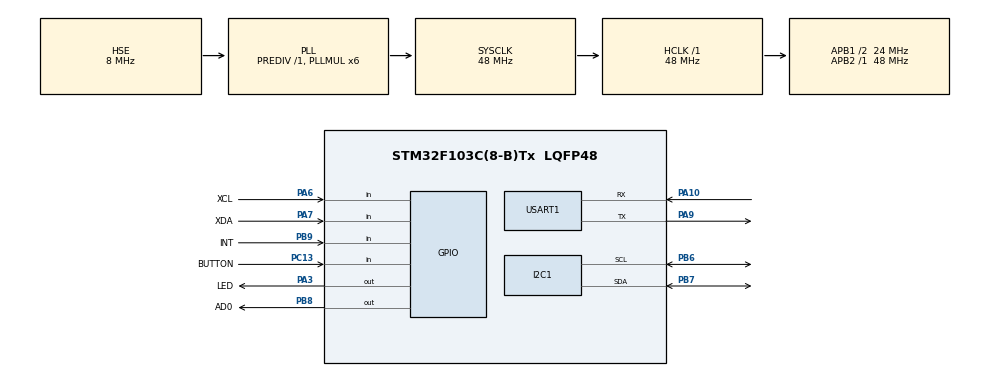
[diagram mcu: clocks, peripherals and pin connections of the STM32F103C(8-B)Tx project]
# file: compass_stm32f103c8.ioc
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Mcu.Family=STM32F1
Mcu.Name=STM32F103C(8-B)Tx
Mcu.Package=LQFP48
NVIC.PriorityGroup=NVIC_PRIORITYGROUP_4
NVIC.TIM2_IRQn=true\:0\:0\:false\:false\:true\:true\:true\:true
NVIC.USART1_IRQn=true\:0\:0\:false\:false\:true\:true\:true\:true
PA10.Mode=Asynchronous
PA10.Signal=USART1_RX
PA13.Mode=Serial_Wire
PA13.Signal=SYS_JTMS-SWDIO
PA14.Mode=Serial_Wire
PA14.Signal=SYS_JTCK-SWCLK
PA3.GPIO_Label=LED
PA3.Signal=GPIO_Output
PA6.GPIO_Label=XCL
PA6.Signal=GPIO_Input
PA7.GPIO_Label=XDA
PA7.Signal=GPIO_Input
PA9.Mode=Asynchronous
PA9.Signal=USART1_TX
PB6.Mode=I2C
PB6.Signal=I2C1_SCL
PB7.Mode=I2C
PB7.Signal=I2C1_SDA
PB8.GPIO_Label=AD0
PB8.GPIO_ModeDefaultOutputPP=GPIO_MODE_OUTPUT_OD
PB8.GPIO_PuPd=GPIO_NOPULL
PB8.PinState=GPIO_PIN_RESET
PB8.Signal=GPIO_Output
PB9.GPIO_Label=INT
PB9.Signal=GPIO_Input
PC13-TAMPER-RTC.GPIO_Label=BUTTON
PC13-TAMPER-RTC.GPIO_PuPd=GPIO_PULLUP
PC13-TAMPER-RTC.Signal=GPIO_Input
PD0-OSC_IN.Mode=HSE-External-Oscillator
PD0-OSC_IN.Signal=RCC_OSC_IN
PD1-OSC_OUT.Mode=HSE-External-Oscillator
PD1-OSC_OUT.Signal=RCC_OSC_OUT
ProjectManager.HeapSize=0x200
ProjectManager.StackSize=0x400
ProjectManager.TargetToolchain=STM32CubeIDE
RCC.AHBFreq_Value=48000000
RCC.APB1CLKDivider=RCC_HCLK_DIV2
RCC.APB1Freq_Value=24000000
RCC.APB1TimFreq_Value=48000000
RCC.APB2Freq_Value=48000000
RCC.APB2TimFreq_Value=48000000
RCC.HCLKFreq_Value=48000000
RCC.PLLMUL=RCC_PLL_MUL6
RCC.PLLSourceVirtual=RCC_PLLSOURCE_HSE
RCC.SYSCLKFreq_VALUE=48000000
RCC.SYSCLKSource=RCC_SYSCLKSOURCE_PLLCLK
RCC.USBFreq_Value=48000000
TIM2.Period=2000-1
TIM2.Prescaler=480-1
USART1.VirtualMode=VM_ASYNC
VP_TIM2_VS_ClockSourceINT.Mode=Internal
board=custom

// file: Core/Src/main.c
/* USER CODE BEGIN Header */
/**
  ******************************************************************************
  * @file           : main.c
  * @brief          : Main program body
  ******************************************************************************
  * @attention
  *
  * Copyright (c) 2023 STMicroelectronics.
  * All rights reserved.
  *
  * This software is licensed under terms that can be found in the LICENSE file
  * in the root directory of this software component.
  * If no LICENSE file comes with this software, it is provided AS-IS.
  *
  ******************************************************************************
  */
/* USER CODE END Header */
#include "main.h"

/* USER CODE BEGIN Includes */
#include "../user/main-app.h"
/* USER CODE END Includes */

I2C_HandleTypeDef hi2c1;

TIM_HandleTypeDef htim2;

UART_HandleTypeDef huart1;

void SystemClock_Config(void);
static void MX_GPIO_Init(void);
static void MX_I2C1_Init(void);
static void MX_USART1_UART_Init(void);
static void MX_TIM2_Init(void);

int main(void)
{

  /* MCU Configuration--------------------------------------------------------*/

  /* Reset of all peripherals, Initializes the Flash interface and the Systick. */
  HAL_Init();

  /* Configure the system clock */
  SystemClock_Config();

  /* USER CODE BEGIN SysInit */
  HAL_Delay(100);
  /* USER CODE END SysInit */

  /* Initialize all configured peripherals */
  MX_GPIO_Init();
  MX_I2C1_Init();
  MX_USART1_UART_Init();
  MX_TIM2_Init();
  /* USER CODE BEGIN 2 */
  mainInit();
  /* USER CODE END 2 */

  /* Infinite loop */
  while (1)
  {

    /* USER CODE BEGIN 3 */
	  mainProcess();
  }
  /* USER CODE END 3 */
}

void SystemClock_Config(void)
{
  RCC_OscInitTypeDef RCC_OscInitStruct = {0};
  RCC_ClkInitTypeDef RCC_ClkInitStruct = {0};

  /** Initializes the RCC Oscillators according to the specified parameters
  * in the RCC_OscInitTypeDef structure.
  */
  RCC_OscInitStruct.OscillatorType = RCC_OSCILLATORTYPE_HSE;
  RCC_OscInitStruct.HSEState = RCC_HSE_ON;
  RCC_OscInitStruct.HSEPredivValue = RCC_HSE_PREDIV_DIV1;
  RCC_OscInitStruct.HSIState = RCC_HSI_ON;
  RCC_OscInitStruct.PLL.PLLState = RCC_PLL_ON;
  RCC_OscInitStruct.PLL.PLLSource = RCC_PLLSOURCE_HSE;
  RCC_OscInitStruct.PLL.PLLMUL = RCC_PLL_MUL6;
  if (HAL_RCC_OscConfig(&RCC_OscInitStruct) != HAL_OK)
  {
    Error_Handler();
  }

  /** Initializes the CPU, AHB and APB buses clocks
  */
  RCC_ClkInitStruct.ClockType = RCC_CLOCKTYPE_HCLK|RCC_CLOCKTYPE_SYSCLK
                              |RCC_CLOCKTYPE_PCLK1|RCC_CLOCKTYPE_PCLK2;
  RCC_ClkInitStruct.SYSCLKSource = RCC_SYSCLKSOURCE_PLLCLK;
  RCC_ClkInitStruct.AHBCLKDivider = RCC_SYSCLK_DIV1;
  RCC_ClkInitStruct.APB1CLKDivider = RCC_HCLK_DIV2;
  RCC_ClkInitStruct.APB2CLKDivider = RCC_HCLK_DIV1;

  if (HAL_RCC_ClockConfig(&RCC_ClkInitStruct, FLASH_LATENCY_1) != HAL_OK)
  {
    Error_Handler();
  }
}

static void MX_I2C1_Init(void)
{

  hi2c1.Instance = I2C1;
  hi2c1.Init.ClockSpeed = 100000;
  hi2c1.Init.DutyCycle = I2C_DUTYCYCLE_2;
  hi2c1.Init.OwnAddress1 = 0;
  hi2c1.Init.AddressingMode = I2C_ADDRESSINGMODE_7BIT;
  hi2c1.Init.DualAddressMode = I2C_DUALADDRESS_DISABLE;
  hi2c1.Init.OwnAddress2 = 0;
  hi2c1.Init.GeneralCallMode = I2C_GENERALCALL_DISABLE;
  hi2c1.Init.NoStretchMode = I2C_NOSTRETCH_DISABLE;
  if (HAL_I2C_Init(&hi2c1) != HAL_OK)
  {
    Error_Handler();
  }

}

static void MX_TIM2_Init(void)
{

  TIM_ClockConfigTypeDef sClockSourceConfig = {0};
  TIM_MasterConfigTypeDef sMasterConfig = {0};

  htim2.Instance = TIM2;
  htim2.Init.Prescaler = 480-1;
  htim2.Init.CounterMode = TIM_COUNTERMODE_UP;
  htim2.Init.Period = 2000-1;
  htim2.Init.ClockDivision = TIM_CLOCKDIVISION_DIV1;
  htim2.Init.AutoReloadPreload = TIM_AUTORELOAD_PRELOAD_DISABLE;
  if (HAL_TIM_Base_Init(&htim2) != HAL_OK)
  {
    Error_Handler();
  }
  sClockSourceConfig.ClockSource = TIM_CLOCKSOURCE_INTERNAL;
  if (HAL_TIM_ConfigClockSource(&htim2, &sClockSourceConfig) != HAL_OK)
  {
    Error_Handler();
  }
  sMasterConfig.MasterOutputTrigger = TIM_TRGO_RESET;
  sMasterConfig.MasterSlaveMode = TIM_MASTERSLAVEMODE_DISABLE;
  if (HAL_TIMEx_MasterConfigSynchronization(&htim2, &sMasterConfig) != HAL_OK)
  {
    Error_Handler();
  }

}

static void MX_USART1_UART_Init(void)
{

  huart1.Instance = USART1;
  huart1.Init.BaudRate = 115200;
  huart1.Init.WordLength = UART_WORDLENGTH_8B;
  huart1.Init.StopBits = UART_STOPBITS_1;
  huart1.Init.Parity = UART_PARITY_NONE;
  huart1.Init.Mode = UART_MODE_TX_RX;
  huart1.Init.HwFlowCtl = UART_HWCONTROL_NONE;
  huart1.Init.OverSampling = UART_OVERSAMPLING_16;
  if (HAL_UART_Init(&huart1) != HAL_OK)
  {
    Error_Handler();
  }

}

static void MX_GPIO_Init(void)
{
  GPIO_InitTypeDef GPIO_InitStruct = {0};

  /* GPIO Ports Clock Enable */
  __HAL_RCC_GPIOC_CLK_ENABLE();
  __HAL_RCC_GPIOD_CLK_ENABLE();
  __HAL_RCC_GPIOA_CLK_ENABLE();
  __HAL_RCC_GPIOB_CLK_ENABLE();

  /*Configure GPIO pin Output Level */
  HAL_GPIO_WritePin(LED_GPIO_Port, LED_Pin, GPIO_PIN_RESET);

  /*Configure GPIO pin Output Level */
  HAL_GPIO_WritePin(AD0_GPIO_Port, AD0_Pin, GPIO_PIN_RESET);

  /*Configure GPIO pin : BUTTON_Pin */
  GPIO_InitStruct.Pin = BUTTON_Pin;
  GPIO_InitStruct.Mode = GPIO_MODE_INPUT;
  GPIO_InitStruct.Pull = GPIO_PULLUP;
  HAL_GPIO_Init(BUTTON_GPIO_Port, &GPIO_InitStruct);

  /*Configure GPIO pin : LED_Pin */
  GPIO_InitStruct.Pin = LED_Pin;
  GPIO_InitStruct.Mode = GPIO_MODE_OUTPUT_PP;
  GPIO_InitStruct.Pull = GPIO_NOPULL;
  GPIO_InitStruct.Speed = GPIO_SPEED_FREQ_LOW;
  HAL_GPIO_Init(LED_GPIO_Port, &GPIO_InitStruct);

  /*Configure GPIO pins : XCL_Pin XDA_Pin */
  GPIO_InitStruct.Pin = XCL_Pin|XDA_Pin;
  GPIO_InitStruct.Mode = GPIO_MODE_INPUT;
  GPIO_InitStruct.Pull = GPIO_NOPULL;
  HAL_GPIO_Init(GPIOA, &GPIO_InitStruct);

  /*Configure GPIO pin : AD0_Pin */
  GPIO_InitStruct.Pin = AD0_Pin;
  GPIO_InitStruct.Mode = GPIO_MODE_OUTPUT_OD;
  GPIO_InitStruct.Pull = GPIO_NOPULL;
  GPIO_InitStruct.Speed = GPIO_SPEED_FREQ_LOW;
  HAL_GPIO_Init(AD0_GPIO_Port, &GPIO_InitStruct);

  /*Configure GPIO pin : INT_Pin */
  GPIO_InitStruct.Pin = INT_Pin;
  GPIO_InitStruct.Mode = GPIO_MODE_INPUT;
  GPIO_InitStruct.Pull = GPIO_NOPULL;
  HAL_GPIO_Init(INT_GPIO_Port, &GPIO_InitStruct);

}

void Error_Handler(void)
{
  __disable_irq();
  while (1)
  {
  }
}
